# psoc4100sp256kb register map
Vendor: Infineon Technologies; Series: PSOC4100Sp256KB; File version: 1.0
CPU: CM0PLUS r0p1, little endian, MPU, no FPU, VTOR, 2 interrupt priority bits, 29 interrupts
Registers are 32-bit, read-write, reset 0x0 unless marked. A register's access mark holds for its fields unless they carry their own. Offsets are from the block's base; [hi:lo] are bit positions.

## MCA0 — Motor Control Accellerator
Base 0x402C0000
Same registers: MCA1 0x402C1000
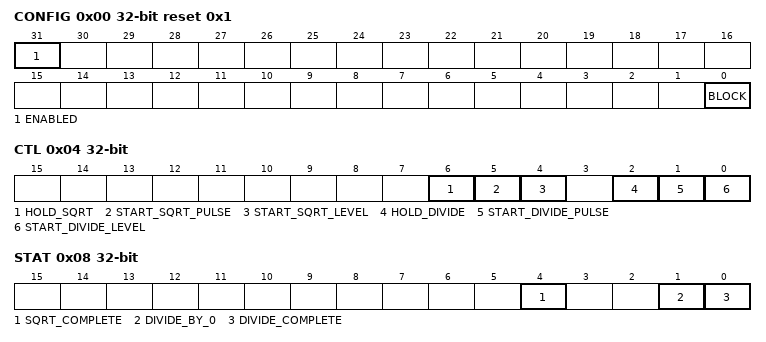
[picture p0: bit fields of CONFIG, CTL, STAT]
0x00 CONFIG reset 0x1 — IP Configuration Register
  [31] ENABLED — Enable IP
  [0] BLOCK — Specify whether a SW read access of DIV_QUOTIENT, DIV_REMAINDER or SQRT_ROOT should block and result in bus wait states while operation is ongoing. 0: Read access returns immediately. It will return stale result if current operation doesn't complete. 1: Introduce wait state if read access is issued while operation is ongoing. It ensures SW to get the calculation result of current operation.
0x04 CTL — IP Control Register
  [6] HOLD_SQRT — Hold Square Root operation.- Pauses the calculation process. If asserted while caculation is in process the STAT.SQRT_COMPLETE to remain low until HOLD is removed. Upon removal - the operation will finish and STAT.SQRT_COMPLETE will assert nominally.
  [5] START_SQRT_PULSE wo write-1-sets — START_SQRT_PULSE: Start Divisor operation - a 1 clock pulse is sent to the SQR.START input. Use this bit OR CTL.START_SQRT_LEVEL, but not both bits simultaneously 0: No Opereration. 1: Create 1 clock pulse to SQR.START
  [4] START_SQRT_LEVEL — Start Square Root operation Level - Use to continuously enable Square Root operations. The divisison begins upon loading SRQ_RADICAND. Use this bit OR CTL.START_SQRT_PULSE, but not both bits simultaneously. 0: SQR.START is disabled. This is the required value if CTL.START_SQRT_PULSE is used. 1: SQR.START is asserted continuously.
  [2] HOLD_DIVIDE — Hold Divide operation.- Pauses the calculation process. If asserted while caculation is in process the STAT.DIVIDE_COMPLETE to remain low until HOLD is removed. Upon removal - the operation will finish and STAT.SQRT_COMPLETE will assert nominally.
  [1] START_DIVIDE_PULSE wo write-1-sets — START_DIVIDE_PULSE: Start Divisor operation - a 1 clock pulse is sent to the DIVIDE.START input. Use either this bit OR CTL.START_DIVIDE_LEVEL, but not both simultaneously. 0: No Opereration. 1: Create 1 clock pulse to DIVIDE.START
  [0] START_DIVIDE_LEVEL — Start Divide operation Level - Use to continuously enable Divide operations. DIV_DIVIDEND must be loaded prior to DIV_DIVISOR. The divisison begins upon loading DIV_DIVISOR. Use either this bit OR CTL.START_DIVIDE_PULSE, but not both simultaneously. 0: DIVDE.START is disabled. This is the required value if CTL.START_DIVIDE_PULSE is used. 1: DIVIDE.START is asserted continuously.
0x08 STAT ro — IP Status Register
  [4] SQRT_COMPLETE — Square Root Operation Complete - This bit is a reflection of the calculation time after SQRT.START de-asserts. 0: Square Root operation is ongoing. 1: Square Root operation completes and ready for next start event. Note that this bit will assert in 4 clk_sys cycles after IP is enabled, even there is no start event.
  [1] DIVIDE_BY_0 — DIV_DIVSOR equals 0
  [0] DIVIDE_COMPLETE — Divide Operation Complete - This bit is a reflection of the calculation time after DIVIDE.START de-asserts. 0: Divide operation is ongoing. 1: Divide operation completes and ready for next start event. Note that this bit will assert in 8 clk_sys cycles after IP is enabled, even there is no start event.
0x10 DIV_DIVIDEND — 32 bit Dividend
0x14 DIV_DIVISOR reset 0x1 — 32 bit Divisor
  [31:0] DIVISOR — Divisor - should not be set to 0 or STAT.DIVIDE_BY_0 will set. If CTL.START_DIVIDE_LEVEL is used, then the divide operation starts once SW writes this register, therefore this register must be programed after DIV_DIVIDEND. After 8 clk_sys cycle, the result will be stored in DIV_QUOTIENT and DIV_REMAINDER. Note that when CTL.START_DIVIDE_LEVEL is asserted, this causes a single DIVIDE.START pulse to begin the calculation.
0x18 DIV_QUOTIENT ro — 32 bit Quotient
  [31:0] QUOTIENT — Quotient. The result will remain unchanged until the next divider operation starts.
0x1C DIV_REMAINDER ro — 32 bit Remainder
  [31:0] REMAINDER — Remainder. The result will remain unchanged until the next divider operation starts.
0x20 SQRT_RADICAND — Square Root Source Value
  [31:0] RADICAND — If CTL.START_SQRT_LEVEL is used, then the square root operation starts once SW writes this register. After 4 clk_sys cycles, the result will be available in SQRT_ROOT. If CTL.START_SQRT_PULSE is used, the result will be available 4 clk_sys cycles after the pulse occurs. Note that when CTL.START_SQRT_LEVEL is used, a 1 clock pulse will be sent to SQR.START to begin the calculation.
0x24 SQRT_ROOT ro — Square Root Result
  [15:0] ROOT — The result will keep unchanged until next square root operation starts .
